# CBASS_CENTRAL2_QOS register map
Vendor: Texas Instruments
Peripheral module from a debugger description file (folder am62x).
Registers are 32-bit, read-write, reset 0x7000 unless marked. A register's access mark holds for its fields unless they carry their own. Offsets are as the file gives them; lines under a group give offsets from that group; [hi:lo] are bit positions; {n}, {i} and the like mark numbered series; 'fields as' and 'values as' point back to an identical list; <NAME> marks a mode.

## CBASS_CENTRAL2_QOS
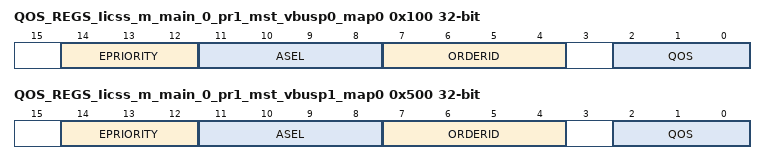
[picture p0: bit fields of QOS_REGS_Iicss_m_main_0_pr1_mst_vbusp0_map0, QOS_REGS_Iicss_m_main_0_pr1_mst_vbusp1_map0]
0x100 QOS_REGS_Iicss_m_main_0_pr1_mst_vbusp0_map0 — The Map Register defines the fields for the master Iicss_m_main_0.pr1_mst_vbusp0 per channel.
  [14:12] EPRIORITY — epriority signal for channel N.
  [11:8] ASEL — asel signal for channel N. 0 = SOC address. 1-15 = peripheral address.
  [7:4] ORDERID — orderid signal for channel N.
  [2:0] QOS — qos signal for channel N.
0x500 QOS_REGS_Iicss_m_main_0_pr1_mst_vbusp1_map0 — The Map Register defines the fields for the master Iicss_m_main_0.pr1_mst_vbusp1 per channel.
  fields as QOS_REGS_Iicss_m_main_0_pr1_mst_vbusp0_map0
